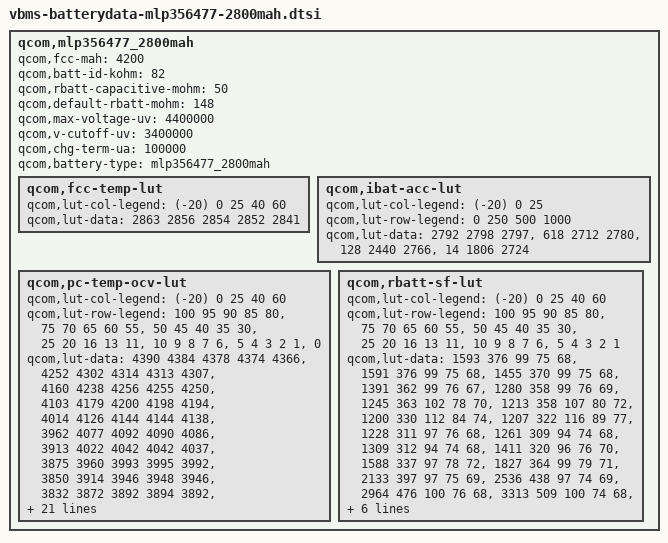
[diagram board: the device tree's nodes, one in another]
/* Copyright (c) 2018 The Linux Foundation. All rights reserved.
 *
 * This program is free software; you can redistribute it and/or modify
 * it under the terms of the GNU General Public License version 2 and
 * only version 2 as published by the Free Software Foundation.
 *
 * This program is distributed in the hope that it will be useful,
 * but WITHOUT ANY WARRANTY; without even the implied warranty of
 * MERCHANTABILITY or FITNESS FOR A PARTICULAR PURPOSE.  See the
 * GNU General Public License for more details.
 */

qcom,mlp356477_2800mah {
	qcom,fcc-mah = <4200>;
	qcom,batt-id-kohm = <82>;
	qcom,rbatt-capacitive-mohm = <50>;
	qcom,default-rbatt-mohm = <148>;
	qcom,max-voltage-uv = <4400000>;
	qcom,v-cutoff-uv = <3400000>;
	qcom,chg-term-ua = <100000>;
	qcom,battery-type = "mlp356477_2800mah";

	qcom,fcc-temp-lut {
		qcom,lut-col-legend = <(-20) 0 25 40 60>;
		qcom,lut-data = <2863 2856 2854 2852 2841>;
	};

	qcom,ibat-acc-lut {
		qcom,lut-col-legend = <(-20) 0 25>;
		qcom,lut-row-legend = <0 250 500 1000>;
		qcom,lut-data = <2792 2798 2797>,
				<618 2712 2780>,
				<128 2440 2766>,
				<14 1806 2724>;
	};

	qcom,pc-temp-ocv-lut {
		qcom,lut-col-legend = <(-20) 0 25 40 60>;
		qcom,lut-row-legend = <100 95 90 85 80>,
					<75 70 65 60 55>,
					<50 45 40 35 30>,
					<25 20 16 13 11>,
					<10 9 8 7 6>,
					<5 4 3 2 1>,
					<0>;
		qcom,lut-data = <4390 4384 4378 4374 4366>,
				<4252 4302 4314 4313 4307>,
				<4160 4238 4256 4255 4250>,
				<4103 4179 4200 4198 4194>,
				<4014 4126 4144 4144 4138>,
				<3962 4077 4092 4090 4086>,
				<3913 4022 4042 4042 4037>,
				<3875 3960 3993 3995 3992>,
				<3850 3914 3946 3948 3946>,
				<3832 3872 3892 3894 3892>,
				<3816 3839 3858 3860 3859>,
				<3802 3814 3832 3834 3832>,
				<3787 3798 3810 3812 3811>,
				<3771 3785 3792 3794 3792>,
				<3754 3772 3774 3774 3768>,
				<3734 3756 3756 3749 3738>,
				<3712 3734 3734 3726 3714>,
				<3692 3712 3712 3704 3690>,
				<3672 3698 3692 3684 3674>,
				<3656 3689 3686 3680 3669>,
				<3646 3685 3685 3679 3668>,
				<3634 3681 3683 3678 3666>,
				<3620 3676 3680 3676 3664>,
				<3604 3668 3676 3670 3654>,
				<3580 3651 3660 3652 3630>,
				<3550 3620 3625 3614 3590>,
				<3508 3574 3575 3565 3538>,
				<3445 3510 3510 3500 3470>,
				<3350 3420 3421 3413 3377>,
				<3182 3274 3282 3266 3232>,
				<3000 3000 3000 3000 3000>;
	};

	qcom,rbatt-sf-lut {
		qcom,lut-col-legend = <(-20) 0 25 40 60>;
		qcom,lut-row-legend = <100 95 90 85 80>,
					<75 70 65 60 55>,
					<50 45 40 35 30>,
					<25 20 16 13 11>,
					<10 9 8 7 6>,
					<5 4 3 2 1>;
		qcom,lut-data = <1593 376 99 75 68>,
				<1591 376 99 75 68>,
				<1455 370 99 75 68>,
				<1391 362 99 76 67>,
				<1280 358 99 76 69>,
				<1245 363 102 78 70>,
				<1213 358 107 80 72>,
				<1200 330 112 84 74>,
				<1207 322 116 89 77>,
				<1228 311 97 76 68>,
				<1261 309 94 74 68>,
				<1309 312 94 74 68>,
				<1411 320 96 76 70>,
				<1588 337 97 78 72>,
				<1827 364 99 79 71>,
				<2133 397 97 75 69>,
				<2536 438 97 74 69>,
				<2964 476 100 76 68>,
				<3313 509 100 74 68>,
				<3539 520 100 76 68>,
				<3793 536 101 76 70>,
				<4098 558 104 78 72>,
				<4461 581 108 82 76>,
				<4893 605 112 84 77>,
				<5421 626 114 82 72>,
				<6107 646 111 79 72>,
				<7007 676 114 80 72>,
				<8309 727 119 82 76>,
				<10285 857 130 89 84>,
				<14336 1715 261 178 168>;
	};
};
